# STM32WL33 register map
File version: 1.0
CPU: CM0+ r0p0, little endian, MPU, no FPU, 4 interrupt priority bits
Registers are 32-bit, read-write, reset 0x0 unless marked. A register's access mark holds for its fields unless they carry their own. Offsets are from the block's base; [hi:lo] are bit positions.

## CRC
Base 0x48200000
0x00 DR reset 0xFFFFFFFF — CRC_DR register
  [31:0] DR — Data register bits. This register is used to write new data to the CRC calculator. It holds the previous CRC calculation result when it is read. If the data size is less than 32 bits, the least significant bits are used to write/read the correct value.
0x04 IDR — CRC_IDR register
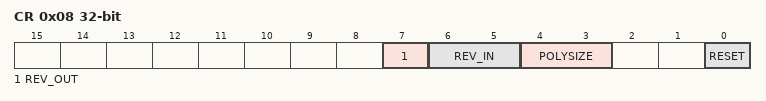
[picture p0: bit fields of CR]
0x08 CR — CRC_CR register
  [7] REV_OUT — Reverse output data This bit controls the reversal of the bit order of the output data. -0: Bit order not affected -1: Bit-reversed output format
  [6:5] REV_IN — Reverse input data These bits control the reversal of the bit order of the input data -00: Bit order not affected -01: Bit reversal done by byte -10: Bit reversal done by half-word -11: Bit reversal done by word
  [4:3] POLYSIZE — Polynomial size These bits control the size of the polynomial. -00: 32 bit polynomial -01: 16 bit polynomial -10: 8 bit polynomial -11: 7 bit polynomial
  [0] RESET — RESET bit This bit is set by software to reset the CRC calculation unit and set the data register to the value stored in the CRC_INIT register. This bit can only be set, it is automatically cleared by hardware
0x10 INIT reset 0xFFFFFFFF — CRC_INIT register
  [31:0] INIT — Programmable initial CRC value This register is used to write the CRC initial value.
0x14 POL reset 0x4C11DB7 — CRC_POL register
  [31:0] POL — POL[31:0]: Programmable polynomial This register is used to write the coefficients of the polynomial to be used for CRC calculation. If the polynomial size is less than 32 bits, the least significant bits have to be used to program the correct value.

## COMP — COMP address block description
Base 0x40009000
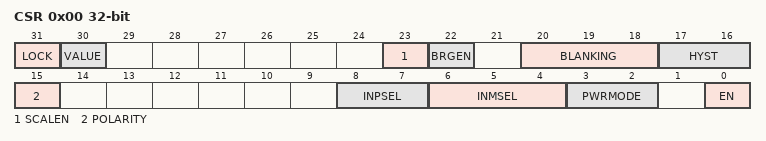
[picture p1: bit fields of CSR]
0x00 CSR
  [31] LOCK ro — LOCK: COMP_CSR register lock bit This bit is set by software and cleared by a hardware system reset. It locks the whole content of the comparator control register, COMP1_CSR[31:0]. 0: COMP1_CSR[31:0] are read/write 1: COMP1_CSR[31:0] are read-only
  [30] VALUE ro — VALUE: Comparator output status bit This bit is read-only. It reflects the current comparator output taking into account POLARITY bit effect.
  [23] SCALEN — SCALEN: Voltage scaler enable bit This bit is set and cleared by software. This bit enable the outputs of the VREFINT divider available on the minus input of the Comparator 0: scaler disable 1: scaler enable
  [22] BRGEN — BRGEN: Scaler bridge enable This bit is set and cleared by software (only if LOCK not set). This bit enable the bridge of the scaler. 0: Scaler resistor bridge disable 1: Scaler resistor bridge enable If SCALEN is set and BRGEN is reset, BG voltage reference is available but not 1/4BGAP, 1/2BGAP, 3/4 BGAP. BGAP value is sent instead of 1/4BGAP, 1/2BGAP, 3/4 BGAP. If SCALEN and BRGEN are set, 1/4 BGAP 1/2BGAP 3/4BGAP and BGAP voltage references are available.
  [20:18] BLANKING — BLANKING[2:0]: Comparator blanking source selection bits These bits select which timer output controls the comparator output blanking. 000: No blanking 001: TIM2 OC4 selected as blanking source 010: TIM16 OC1 selected as blanking source All other values: reserved
  [17:16] HYST — HYST[1:0]: Comparator hysteresis selection bits These bits are set and cleared by software (only if LOCK not set). They select the Hysteresis voltage of the comparator . 00: No hysteresis 01: Low hysteresis 10: Medium hysteresis 11: High hysteresis
  [15] POLARITY — POLARITY: Comparator polarity selection bit This bit is set and cleared by software (only if LOCK not set). It inverts Comparator polarity. 0: Comparator output value not inverted 1: Comparator output value inverted
  [8:7] INPSEL — INPSEL[1:0]: Comparator input plus selection bit This bit is set and cleared by software (only if LOCK not set). 00: PA14 01: PB1 1x: PB2
  [6:4] INMSEL — INMSEL: Comparator input minus selection bits These bits are set and cleared by software (only if LOCK not set). They select which input is connected to the input minus of comparator. 000: 1/4 VREFINT 001: 1/2 VREFINT 010: 3/4VREFINT 011: VREFINT 100: DAC OUT 101: PA13 110: PB0 111: PB3
  [3:2] PWRMODE — PWRMODE[1:0]: Power Mode of the comparator These bits are set and cleared by software (only if LOCK not set). They control the power/speed of the Comparator. 00:High speed 01 or 10:Medium speed 11:Ultra low power
  [0] EN — EN: Comparator enable bit This bit is set and cleared by software (only if LOCK not set). It switches on Comparator. 0: Comparator switched OFF 1: Comparator switched ON
